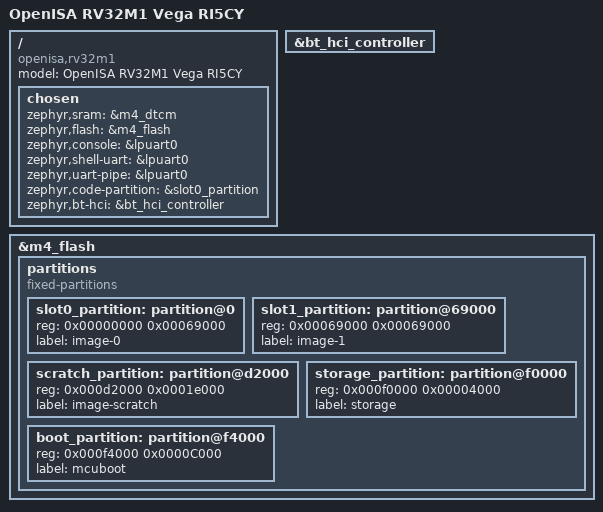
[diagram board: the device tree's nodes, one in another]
/*
 * Copyright 2018 Foundries.io Ltd
 * SPDX-License-Identifier: Apache-2.0
 */

/dts-v1/;

#include "openisa/rv32m1_ri5cy.dtsi"
#include "rv32m1_vega_openisa_rv32m1.dtsi"

/ {
	compatible = "openisa,rv32m1";
	model = "OpenISA RV32M1 Vega RI5CY";

	chosen {
		zephyr,sram = &m4_dtcm;
		zephyr,flash = &m4_flash;
		zephyr,console = &lpuart0;
		zephyr,shell-uart = &lpuart0;
		zephyr,uart-pipe = &lpuart0;
		zephyr,code-partition = &slot0_partition;
		zephyr,bt-hci = &bt_hci_controller;
	};
};

&bt_hci_controller {
	status = "okay";
};

&m4_flash {
	/*
	 * For more information, see:
	 * http://docs.zephyrproject.org/latest/guides/dts/index.html
	 */
	partitions {
		compatible = "fixed-partitions";
		#address-cells = <1>;
		#size-cells = <1>;

		slot0_partition: partition@0 {
			reg = <0x00000000 0x00069000>;
			label = "image-0";
		};

		slot1_partition: partition@69000 {
			reg = <0x00069000 0x00069000>;
			label = "image-1";
		};

		scratch_partition: partition@d2000 {
			reg = <0x000d2000 0x0001e000>;
			label = "image-scratch";
		};

		storage_partition: partition@f0000 {
			reg = <0x000f0000 0x00004000>;
			label = "storage";
		};

		boot_partition: partition@f4000 {
			reg = <0x000f4000 0x0000C000>;
			label = "mcuboot";
		};
	};
};
